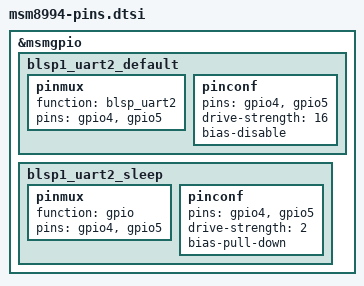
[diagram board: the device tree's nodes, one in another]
// SPDX-License-Identifier: GPL-2.0-only
/*
 * Copyright (c) 2013-2016, The Linux Foundation. All rights reserved.
 */

&msmgpio {
	blsp1_uart2_default: blsp1_uart2_default {
		pinmux {
			function = "blsp_uart2";
			pins = "gpio4", "gpio5";
		};
		pinconf {
			pins = "gpio4", "gpio5";
			drive-strength = <16>;
			bias-disable;
		};
	};

	blsp1_uart2_sleep: blsp1_uart2_sleep {
		pinmux {
			function = "gpio";
			pins = "gpio4", "gpio5";
		};
		pinconf {
			pins = "gpio4", "gpio5";
			drive-strength = <2>;
			bias-pull-down;
		};
	};
};
